# CY8C5888LTI_LP097 register map
File version: 0.1
CY8C58LP
Registers are 8-bit, read-write, no defined reset value unless marked. A register's access mark holds for its fields unless they carry their own. Offsets are from the block's base; lines under a group give offsets from that group; [hi:lo] are bit positions; {n}, {i} and the like mark numbered series; 'fields as' and 'values as' point back to an identical list; <NAME> marks a mode.

## Memory map
0x00000000 DEBUG_UART — UART
0x00000000 I2C
0x00000000 ADC_DelSig

## DEBUG_UART — UART
Base 0x00000000
0x40006444 TX_DEBUG_UART_TX_DATA — TX Data Register
0x4000652A RX_DEBUG_UART_RX_ADDRESS1 — RX Address1 Register
0x4000653A RX_DEBUG_UART_RX_ADDRESS2 — RX Address2 Register
0x4000654A RX_DEBUG_UART_RX_DATA — RX Data Register
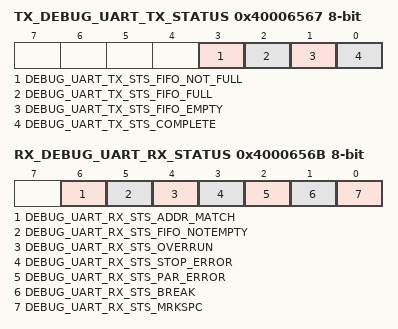
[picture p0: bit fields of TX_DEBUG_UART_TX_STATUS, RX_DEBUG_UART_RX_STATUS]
0x40006567 TX_DEBUG_UART_TX_STATUS — TX status register
  [3] DEBUG_UART_TX_STS_FIFO_NOT_FULL ro, [2] DEBUG_UART_TX_STS_FIFO_FULL ro, [1] DEBUG_UART_TX_STS_FIFO_EMPTY ro, [0] DEBUG_UART_TX_STS_COMPLETE ro
0x4000656B RX_DEBUG_UART_RX_STATUS — RX status register
  [6] DEBUG_UART_RX_STS_ADDR_MATCH ro, [5] DEBUG_UART_RX_STS_FIFO_NOTEMPTY ro, [4] DEBUG_UART_RX_STS_OVERRUN ro, [3] DEBUG_UART_RX_STS_STOP_ERROR ro, [2] DEBUG_UART_RX_STS_PAR_ERROR ro, [1] DEBUG_UART_RX_STS_BREAK ro, [0] DEBUG_UART_RX_STS_MRKSPC ro

## I2C
Base 0x00000000
0x40006406 I2C_DATA
  [7:0] data — Read received data or write data to transmit. These bits are held zero if I2C_CFG.en_mstr and I2C_CFG.en_slave are both zero.
0x40006426 I2C_ADDR — I2C Slave Adddress Register
  [6:0] slave_address — These seven bits hold the slave's own device address.
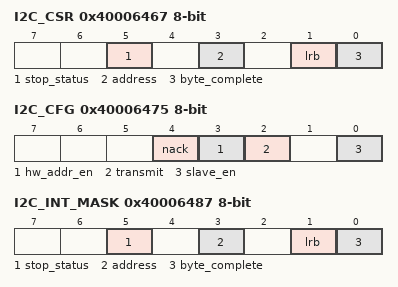
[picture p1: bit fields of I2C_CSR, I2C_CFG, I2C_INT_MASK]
0x40006467 I2C_CSR — I2C Status Register
  [5] stop_status ro — If set, indicates a Stop condition was detected on the bus.
  [3] address ro — Address detection. If set, indicates that an address byte was sent.
  [1] lrb ro — Last Received Bit. Indicates the state of the last received bit, which is the ACK/NAK received for the last byte transmitted. Cleared = ACK and set = NAK.
  [0] byte_complete ro — Transmit or receive status since the last read of this register. In Transmit mode this bit indicates that eight bits of data plus ACK/NAK have been transmitted since the last read. In Receive mode this bit indicates that eight bits of data have been received since the last read of this register.
0x40006475 I2C_CFG — I2C Configuration Register
  [4] nack — If set, used to NAK the last byte received. This bit must be cleared by firmware between bytes.
  [3] hw_addr_en — If set, used to enable the device to respond any device addresses it receives rather than just the single address provided in I2C_ADDRESS.
  [2] transmit — Used to set the mode to transmit or receive data. This bit must be cleared by firmware between bytes. Set = transmit and cleared = receive.
  [0] slave_en — Set to 1 to enable the slave functionality.
0x40006487 I2C_INT_MASK — I2C Interrupt Enable Mask
  [5] stop_status — Enables interrupt from the corresponding bit in status register.
  [3] address — Enables interrupt from the corresponding bit in status register.
  [1] lrb — Enables interrupt from the corresponding bit in status register.
  [0] byte_complete — Enables interrupt from the corresponding bit in status register.
